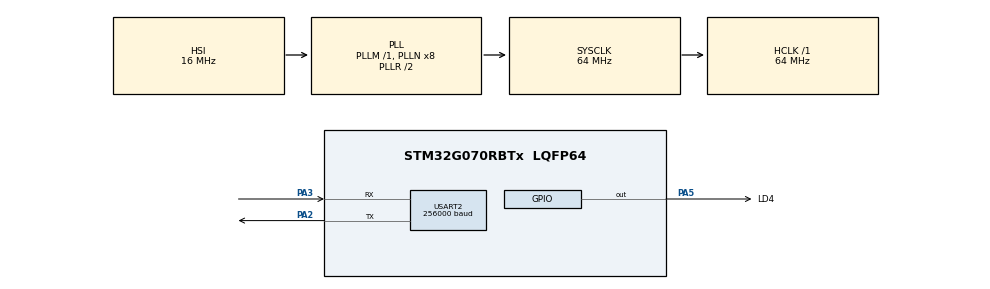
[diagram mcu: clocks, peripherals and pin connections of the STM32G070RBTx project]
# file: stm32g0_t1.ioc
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ADC1.Channel-0\#ChannelRegularConversion=ADC_CHANNEL_TEMPSENSOR
ADC1.Channel-1\#ChannelRegularConversion=ADC_CHANNEL_VREFINT
ADC1.Channel-2\#ChannelRegularConversion=ADC_CHANNEL_VBAT
ADC1.ContinuousConvMode=ENABLE
ADC1.DMAContinuousRequests=ENABLE
ADC1.EnableAnalogWatchDog1=true
ADC1.NbrOfConversion=3
ADC1.NbrOfConversionFlag=1
ADC1.Rank-0\#ChannelRegularConversion=1
ADC1.Rank-1\#ChannelRegularConversion=2
ADC1.Rank-2\#ChannelRegularConversion=3
ADC1.SamplingTime-0\#ChannelRegularConversion=ADC_SAMPLINGTIME_COMMON_1
ADC1.SamplingTime-1\#ChannelRegularConversion=ADC_SAMPLINGTIME_COMMON_1
ADC1.SamplingTime-2\#ChannelRegularConversion=ADC_SAMPLINGTIME_COMMON_1
ADC1.SamplingTimeCommon1=ADC_SAMPLETIME_160CYCLES_5
ADC1.SamplingTimeCommon2=ADC_SAMPLETIME_160CYCLES_5
ADC1.WatchdogChannel=ADC_CHANNEL_TEMPSENSOR
ADC1.master=1
Dma.ADC1.0.Direction=DMA_PERIPH_TO_MEMORY
Dma.ADC1.0.EventEnable=DISABLE
Dma.ADC1.0.Instance=DMA1_Channel1
Dma.ADC1.0.MemDataAlignment=DMA_MDATAALIGN_HALFWORD
Dma.ADC1.0.MemInc=DMA_MINC_ENABLE
Dma.ADC1.0.Mode=DMA_CIRCULAR
Dma.ADC1.0.PeriphDataAlignment=DMA_PDATAALIGN_HALFWORD
Dma.ADC1.0.PeriphInc=DMA_PINC_DISABLE
Dma.ADC1.0.Polarity=HAL_DMAMUX_REQ_GEN_RISING
Dma.ADC1.0.Priority=DMA_PRIORITY_LOW
Dma.ADC1.0.RequestNumber=1
Dma.ADC1.0.SignalID=NONE
Dma.ADC1.0.SyncEnable=DISABLE
Dma.ADC1.0.SyncPolarity=HAL_DMAMUX_SYNC_NO_EVENT
Dma.ADC1.0.SyncRequestNumber=1
Dma.ADC1.0.SyncSignalID=NONE
Dma.Request0=ADC1
Dma.Request1=USART2_RX
Dma.Request2=USART2_TX
Dma.USART2_RX.1.Direction=DMA_PERIPH_TO_MEMORY
Dma.USART2_RX.1.EventEnable=DISABLE
Dma.USART2_RX.1.Instance=DMA1_Channel2
Dma.USART2_RX.1.MemDataAlignment=DMA_MDATAALIGN_BYTE
Dma.USART2_RX.1.MemInc=DMA_MINC_ENABLE
Dma.USART2_RX.1.Mode=DMA_NORMAL
Dma.USART2_RX.1.PeriphDataAlignment=DMA_PDATAALIGN_BYTE
Dma.USART2_RX.1.PeriphInc=DMA_PINC_DISABLE
Dma.USART2_RX.1.Polarity=HAL_DMAMUX_REQ_GEN_RISING
Dma.USART2_RX.1.Priority=DMA_PRIORITY_LOW
Dma.USART2_RX.1.RequestNumber=1
Dma.USART2_RX.1.SignalID=NONE
Dma.USART2_RX.1.SyncEnable=DISABLE
Dma.USART2_RX.1.SyncPolarity=HAL_DMAMUX_SYNC_NO_EVENT
Dma.USART2_RX.1.SyncRequestNumber=1
Dma.USART2_RX.1.SyncSignalID=NONE
Dma.USART2_TX.2.Direction=DMA_MEMORY_TO_PERIPH
Dma.USART2_TX.2.EventEnable=DISABLE
Dma.USART2_TX.2.Instance=DMA1_Channel3
Dma.USART2_TX.2.MemDataAlignment=DMA_MDATAALIGN_BYTE
Dma.USART2_TX.2.MemInc=DMA_MINC_ENABLE
Dma.USART2_TX.2.Mode=DMA_NORMAL
Dma.USART2_TX.2.PeriphDataAlignment=DMA_PDATAALIGN_BYTE
Dma.USART2_TX.2.PeriphInc=DMA_PINC_DISABLE
Dma.USART2_TX.2.Polarity=HAL_DMAMUX_REQ_GEN_RISING
Dma.USART2_TX.2.Priority=DMA_PRIORITY_LOW
Dma.USART2_TX.2.RequestNumber=1
Dma.USART2_TX.2.SignalID=NONE
Dma.USART2_TX.2.SyncEnable=DISABLE
Dma.USART2_TX.2.SyncPolarity=HAL_DMAMUX_SYNC_NO_EVENT
Dma.USART2_TX.2.SyncRequestNumber=1
Dma.USART2_TX.2.SyncSignalID=NONE
Mcu.Family=STM32G0
Mcu.Name=STM32G070RBTx
Mcu.Package=LQFP64
NVIC.DMA1_Channel1_IRQn=true\:0\:0\:false\:false\:true\:false\:true
NVIC.DMA1_Channel2_3_IRQn=true\:0\:0\:false\:false\:true\:false\:true
PA13.GPIO_Label=TMS
PA13.Mode=Serial_Wire
PA13.Signal=SYS_SWDIO
PA14-BOOT0.GPIO_Label=TCK
PA14-BOOT0.Mode=Serial_Wire
PA14-BOOT0.Signal=SYS_SWCLK
PA2.Mode=Asynchronous
PA2.Signal=USART2_TX
PA3.Mode=Asynchronous
PA3.Signal=USART2_RX
PA5.GPIO_Label=LD4
PA5.Signal=GPIO_Output
PC13.Mode=SYS_WakeUp1
PC13.Signal=SYS_WKUP2
PC14-OSC32_IN\ (PC14).Mode=LSE-External-Oscillator
PC14-OSC32_IN\ (PC14).Signal=RCC_OSC32_IN
PC15-OSC32_OUT\ (PC15).Mode=LSE-External-Oscillator
PC15-OSC32_OUT\ (PC15).Signal=RCC_OSC32_OUT
PF0-OSC_IN\ (PF0).GPIO_Label=MCO
PF0-OSC_IN\ (PF0).Mode=HSE-External-Clock-Source
PF0-OSC_IN\ (PF0).Signal=RCC_OSC_IN
ProjectManager.HeapSize=0x200
ProjectManager.StackSize=0x400
ProjectManager.TargetToolchain=MDK-ARM V5
RCC.ADCFreq_Value=64000000
RCC.AHBFreq_Value=64000000
RCC.CortexFreq_Value=64000000
RCC.EXTERNAL_CLOCK_VALUE=12288000
RCC.HCLKFreq_Value=64000000
RCC.HSE_VALUE=8000000
RCC.HSI_VALUE=16000000
RCC.SYSCLKFreq_VALUE=64000000
RCC.SYSCLKSource=RCC_SYSCLKSOURCE_PLLCLK
RCC.VCOOutputFreq_Value=128000000
USART2.BaudRate=256000
USART2.VirtualMode-Asynchronous=VM_ASYNC
USART2.WordLength=WORDLENGTH_8B
VP_ADC1_TempSens_Input.Mode=IN-TempSens
VP_ADC1_Vbat_Input.Mode=IN-Vbat
VP_ADC1_Vref_Input.Mode=IN-Vrefint
VP_CRC_VS_CRC.Mode=CRC_Activate
board=NUCLEO-G070RB

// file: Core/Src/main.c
/* USER CODE BEGIN Header */
/**
  ******************************************************************************
  * @file           : main.c
  * @brief          : Main program body
  ******************************************************************************
  * @attention
  *
  * <h2><center>&copy; Copyright (c) 2019 STMicroelectronics.
  * All rights reserved.</center></h2>
  *
  * This software component is licensed by ST under BSD 3-Clause license,
  * the "License"; You may not use this file except in compliance with the
  * License. You may obtain a copy of the License at:
  *                        opensource.org/licenses/BSD-3-Clause
  *
  ******************************************************************************
  */
/* USER CODE END Header */

#include "main.h"
#include "adc.h"
#include "crc.h"
#include "dma.h"
#include "usart.h"
#include "gpio.h"

/* USER CODE BEGIN Includes */
#include <stdio.h>
#include <stdint.h>
#include <stdlib.h>
#include "asm_prototype.h"
#include "stm32_mpu.h"
/* USER CODE END Includes */

void SystemClock_Config(void);

/* USER CODE BEGIN 0 */
#if defined(__ARMCC_VERSION)
int stdout_putchar (int ch) {
	uint8_t c = ch;
	HAL_UART_Transmit(&huart2, &c, 1, 1);
	return ch;
}
#else
int _write (int fd, const void *buf, size_t count) {
	for(uint32_t i=0; i<count; ++i) {
		HAL_UART_Transmit(&huart2, buf+i, 1, 1);
	}
	return count;
}
#endif

volatile uint16_t g_adc_buf[3];

#define SP_PROCESS                  0x02   /* Process stack */
#define SP_MAIN                     0x00   /* Main stack */
#define THREAD_MODE_PRIVILEGED      0x00   /* Thread mode has privileged access */
#define THREAD_MODE_UNPRIVILEGED    0x01   /* Thread mode has unprivileged access */

extern uint8_t PrivilegedReadOnlyArray[32];

/* USER CODE END 0 */

int main(void)
{

  /* MCU Configuration--------------------------------------------------------*/

  /* Reset of all peripherals, Initializes the Flash interface and the Systick. */
  HAL_Init();

  /* Configure the system clock */
  SystemClock_Config();

  /* Initialize all configured peripherals */
  MX_GPIO_Init();
  MX_DMA_Init();
  MX_ADC1_Init();
  MX_CRC_Init();
  MX_USART2_UART_Init();
  /* USER CODE BEGIN 2 */
  /* Set MPU regions */
  MPU_Config();
  MPU_AccessPermConfig();

	HAL_ADC_Start_DMA(&hadc1, (uint32_t*)g_adc_buf, sizeof(g_adc_buf)/sizeof(g_adc_buf[0]));
	printf("Clock:%u Hz\n", SystemCoreClock);

  /* Switch Thread mode from privileged to unprivileged ------------------------*/
  /* Thread mode has unprivileged access */
  __set_CONTROL(THREAD_MODE_UNPRIVILEGED | SP_MAIN);
  /* Execute ISB instruction to flush pipeline as recommended by Arm */
  __ISB();

  /* USER CODE END 2 */

  /* Infinite loop */
  /* USER CODE BEGIN WHILE */
  while (1)
  {
		printf("ADC:%u %u %u\n", g_adc_buf[0], (g_adc_buf[1]*3300)/4095, (g_adc_buf[2]*3300)/4095);
		HAL_Delay(1000);

		printf("%s %u\n", __func__, __LINE__);
		printf("%s %u %02X\n", __func__, __LINE__, PrivilegedReadOnlyArray[0]);

		asm_svc_2(HAL_GetTick());
		printf("%s %u %02X\n", __func__, __LINE__, PrivilegedReadOnlyArray[0]);

		PrivilegedReadOnlyArray[0] = (uint8_t)HAL_GetTick();
		printf("%s %u %02X\n", __func__, __LINE__, PrivilegedReadOnlyArray[0]);

		HAL_GPIO_TogglePin(LD4_GPIO_Port, LD4_Pin);
    /* USER CODE END WHILE */

  }
}

void SystemClock_Config(void)
{
  RCC_OscInitTypeDef RCC_OscInitStruct = {0};
  RCC_ClkInitTypeDef RCC_ClkInitStruct = {0};
  RCC_PeriphCLKInitTypeDef PeriphClkInit = {0};

  /** Configure the main internal regulator output voltage
  */
  HAL_PWREx_ControlVoltageScaling(PWR_REGULATOR_VOLTAGE_SCALE1);
  /** Initializes the CPU, AHB and APB busses clocks
  */
  RCC_OscInitStruct.OscillatorType = RCC_OSCILLATORTYPE_HSI;
  RCC_OscInitStruct.HSIState = RCC_HSI_ON;
  RCC_OscInitStruct.HSIDiv = RCC_HSI_DIV1;
  RCC_OscInitStruct.HSICalibrationValue = RCC_HSICALIBRATION_DEFAULT;
  RCC_OscInitStruct.PLL.PLLState = RCC_PLL_ON;
  RCC_OscInitStruct.PLL.PLLSource = RCC_PLLSOURCE_HSI;
  RCC_OscInitStruct.PLL.PLLM = RCC_PLLM_DIV1;
  RCC_OscInitStruct.PLL.PLLN = 8;
  RCC_OscInitStruct.PLL.PLLP = RCC_PLLP_DIV2;
  RCC_OscInitStruct.PLL.PLLR = RCC_PLLR_DIV2;
  if (HAL_RCC_OscConfig(&RCC_OscInitStruct) != HAL_OK)
  {
    Error_Handler();
  }
  /** Initializes the CPU, AHB and APB busses clocks
  */
  RCC_ClkInitStruct.ClockType = RCC_CLOCKTYPE_HCLK|RCC_CLOCKTYPE_SYSCLK
                              |RCC_CLOCKTYPE_PCLK1;
  RCC_ClkInitStruct.SYSCLKSource = RCC_SYSCLKSOURCE_PLLCLK;
  RCC_ClkInitStruct.AHBCLKDivider = RCC_SYSCLK_DIV1;
  RCC_ClkInitStruct.APB1CLKDivider = RCC_HCLK_DIV1;

  if (HAL_RCC_ClockConfig(&RCC_ClkInitStruct, FLASH_LATENCY_2) != HAL_OK)
  {
    Error_Handler();
  }
  /** Initializes the peripherals clocks
  */
  PeriphClkInit.PeriphClockSelection = RCC_PERIPHCLK_USART2|RCC_PERIPHCLK_ADC;
  PeriphClkInit.Usart2ClockSelection = RCC_USART2CLKSOURCE_PCLK1;
  PeriphClkInit.AdcClockSelection = RCC_ADCCLKSOURCE_SYSCLK;
  if (HAL_RCCEx_PeriphCLKConfig(&PeriphClkInit) != HAL_OK)
  {
    Error_Handler();
  }
}

void Error_Handler(void)
{
}

/************************ (C) COPYRIGHT STMicroelectronics *****END OF FILE****/
